# R7FA6T2BD register map
Vendor: Renesas Electronics Corporation; Series: RA6; File version: 1.40.00
CPU: CM33 r0p4, little endian, MPU, FPU, VTOR, 4 interrupt priority bits, 96 interrupts
Registers are 32-bit, read-write, reset 0x0 unless marked. A register's access mark holds for its fields unless they carry their own. Offsets are from the block's base; [hi:lo] are bit positions; {n}, {i} and the like mark numbered series.

## ICU — Interrupt Controller
Base 0x40006000
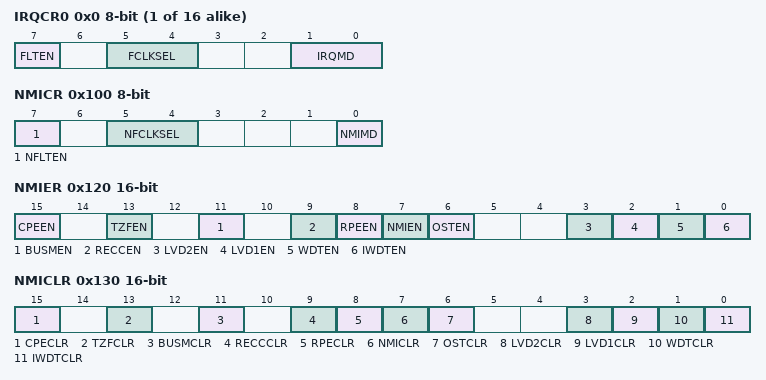
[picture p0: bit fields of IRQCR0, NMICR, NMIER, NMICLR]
{0x0+i} IRQCR{i} (i=0..15) 8-bit — IRQ Control Register {i}
  [7] FLTEN — IRQi Digital Filter Enable
  [5:4] FCLKSEL — IRQi Digital Filter Sampling Clock Select
  [1:0] IRQMD — IRQi Detection Sense Select
0x100 NMICR 8-bit — NMI Pin Interrupt Control Register
  [7] NFLTEN — NMI Digital Filter Enable
  [5:4] NFCLKSEL — NMI Digital Filter Sampling Clock Select
  [0] NMIMD — NMI Detection Set
0x120 NMIER 16-bit — Non,Maskable Interrupt Enable Register
  [15] CPEEN
  [13] TZFEN
  [11] BUSMEN — Bus Master MPU Error Interrupt Enable
  [9] RECCEN — SRAM ECC Error Interrupt Enable
  [8] RPEEN — SRAM Parity Error Interrupt Enable
  [7] NMIEN — NMI Pin Interrupt Enable
  [6] OSTEN — Main Clock Oscillation Stop Detection Interrupt Enable
  [3] LVD2EN — Voltage monitor 2 Interrupt Enable
  [2] LVD1EN — Voltage monitor 1 Interrupt Enable
  [1] WDTEN — WDT Underflow/Refresh Error Interrupt Enable
  [0] IWDTEN — IWDT Underflow/Refresh Error Interrupt Enable
0x130 NMICLR 16-bit — Non,Maskable Interrupt Status Clear Register
  [15] CPECLR
  [13] TZFCLR
  [11] BUSMCLR — Bus Master MPU Error Interrupt Status Flag Clear
  [9] RECCCLR — SRAM ECC Error Interrupt Status Flag Clear
  [8] RPECLR — SRAM Parity Error Interrupt Status Flag Clear
  [7] NMICLR — NMI Pin Interrupt Status Flag Clear
  [6] OSTCLR — Oscillation Stop Detection Interrupt Status Flag Clear
  [3] LVD2CLR — Voltage Monitor 2 Interrupt Status Flag Clear
  [2] LVD1CLR — Voltage Monitor 1 Interrupt Status Flag Clear
  [1] WDTCLR — WDT Underflow/Refresh Error Interrupt Status Flag Clear
  [0] IWDTCLR — IWDT Underflow/Refresh Error Interrupt Status Flag Clear
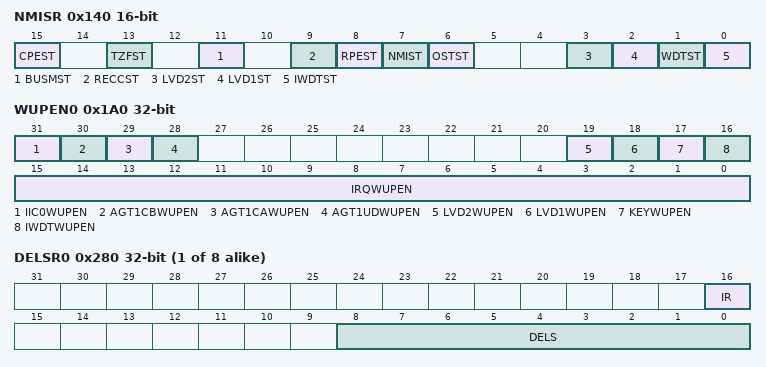
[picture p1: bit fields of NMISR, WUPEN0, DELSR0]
0x140 NMISR 16-bit ro — Non,Maskable Interrupt Status Register
  [15] CPEST
  [13] TZFST
  [11] BUSMST — Bus Master MPU Error Interrupt Status Flag
  [9] RECCST — SRAM ECC Error Interrupt Status Flag
  [8] RPEST — SRAM Parity Error Interrupt Status Flag
  [7] NMIST — NMI Pin Interrupt Status Flag
  [6] OSTST — Main Clock Oscillation Stop Detection Interrupt Status Flag
  [3] LVD2ST — Voltage Monitor 2 Interrupt Status Flag
  [2] LVD1ST — Voltage Monitor 1 Interrupt Status Flag
  [1] WDTST — WDT Underflow/Refresh Error Interrupt Status Flag
  [0] IWDTST — IWDT Underflow/Refresh Error Interrupt Status Flag
0x1A0 WUPEN0 — Wake Up Interrupt Enable Register 0
  [31] IIC0WUPEN — IIC0 Address Match Interrupt Software Standby/Snooze Mode Returns Enable bit
  [30] AGT1CBWUPEN — AGT1 Compare Match B Interrupt Software Standby/Snooze Mode Returns Enable bit
  [29] AGT1CAWUPEN — AGT1 Compare Match A Interrupt Software Standby/Snooze Mode Returns Enable bit
  [28] AGT1UDWUPEN — AGT1 Underflow Interrupt Software Standby/Snooze Mode Returns Enable bit
  [19] LVD2WUPEN — LVD2 Interrupt Software Standby/Snooze Mode Returns Enable bit
  [18] LVD1WUPEN — LVD1 Interrupt Software Standby/Snooze Mode Returns Enable bit
  [17] KEYWUPEN — Key interrupt S/W standby returns enable bit
  [16] IWDTWUPEN — IWDT Interrupt Software Standby/Snooze Mode Returns Enable bit
  [15:0] IRQWUPEN — IRQn Interrupt Software Standby/Snooze Mode Returns Enable bit (n = 0 to 15)
0x200 SELSR0 16-bit — SYS Event Link Setting Register
{0x280+4i} DELSR{i} (i=0..7) — DMAC Event Link Setting Register {i}
  [16] IR — DMAC Activation Request Status Flag
  [8:0] DELS — DMAC Event Link Select
{0x300+4i} IELSR{i} (i=0..95) — ICU Event Link Setting Register {i}

## CACHE
Base 0x40007000
0x00 CCACTL — C,Cache Control Register
  [0] ENC — C,Cache Enable
0x04 CCAFCT — C,Cache Flush Control Register
  [0] FC — C,Cache Flush
0x08 CCALCF reset 0x1 — C,Cache Line Configuration Register
  [1:0] CC — C,Cache Line Size
0x40 SCACTL — S,Cache Control Register
  [0] ENS — S,Cache Enable
0x44 SCAFCT — S,Cache Flush Control Register
  [0] FS — S,Cache Flush
0x48 SCALCF reset 0x1 — S,Cache Line Configuration Register
  [1:0] CS — S,Cache Line Size
0x200 CAPOAD — Cache Parity Error Operation After Detection Register
  [0] OAD — Operation after Detection
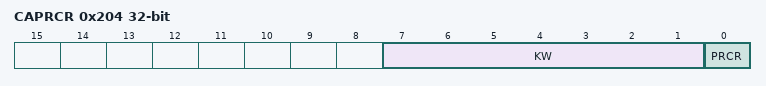
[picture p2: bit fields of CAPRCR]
0x204 CAPRCR — Cache Protection Register
  [7:1] KW — Write key code
  [0] PRCR — Register Write Control

## Notices in the file
This software is supplied by Renesas Electronics Corporation and is only intended for
use with Renesas products. No other uses are authorized. This software is owned by
Renesas Electronics Corporation and is protected under all applicable laws, including
copyright laws.
THIS SOFTWARE IS PROVIDED "AS IS" AND RENESAS MAKES NO WARRANTIES REGARDING
THIS SOFTWARE, WHETHER EXPRESS, IMPLIED OR STATUTORY, INCLUDING BUT NOT LIMITED TO
WARRANTIES OF MERCHANTABILITY, FITNESS FOR A PARTICULAR PURPOSE AND NON-INFRINGEMENT.
ALL SUCH WARRANTIES ARE EXPRESSLY DISCLAIMED. TO THE MAXIMUM EXTENT PERMITTED NOT
PROHIBITED BY LAW, NEITHER RENESAS ELECTRONICS CORPORATION NOR ANY OF ITS AFFILIATED
COMPANIES SHALL BE LIABLE FOR ANY DIRECT, INDIRECT, SPECIAL, INCIDENTAL OR CONSEQUENTIAL
DAMAGES FOR ANY REASON RELATED TO THIS SOFTWARE, EVEN IF RENESAS OR ITS AFFILIATES HAVE
BEEN ADVISED OF THE POSSIBILITY OF SUCH DAMAGES.
Renesas reserves the right, without notice, to make changes to this software and to
discontinue the availability of this software. By using this software, you agree to
the additional terms and conditions found by accessing the following link:
http://www.renesas.com/disclaimer
